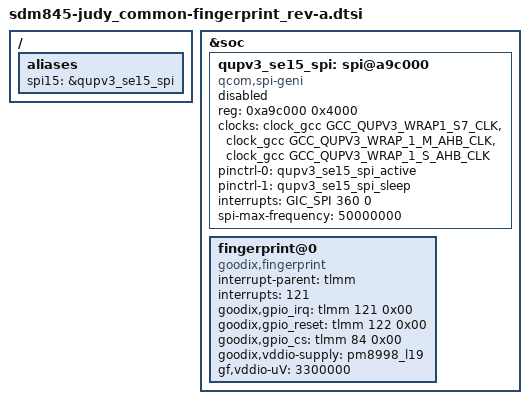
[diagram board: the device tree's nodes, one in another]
/* Copyright (c) 2017, The Linux Foundation. All rights reserved.
 *
 * This program is free software; you can redistribute it and/or modify
 * it under the terms of the GNU General Public License version 2 and
 * only version 2 as published by the Free Software Foundation.
 *
 * This program is distributed in the hope that it will be useful,
 * but WITHOUT ANY WARRANTY; without even the implied warranty of
 * MERCHANTABILITY or FITNESS FOR A PARTICULAR PURPOSE.  See the
 * GNU General Public License for more details.
 */
/{
	aliases {
		spi15 = &qupv3_se15_spi;
	};
/*
	reserved-memory {
		removed_regions: removed_regions@85800000 {
			reg = <0 0x85800000 0 0x2800000>;
		};
	};*/
};

&soc {
/*	qcom_seecom: qseecom@86600000 {
		reg = <0x86600000 0x1A00000>;
	};
*/
	/* PIN CONTROL for gf3208 */

	qupv3_se15_spi: spi@a9c000 { /* QUP15 */
		compatible = "qcom,spi-geni";
		#address-cells = <1>;
		#size-cells = <0>;
		reg = <0xa9c000 0x4000>;
		reg-names = "se_phys";
		clock-names = "se-clk", "m-ahb", "s-ahb";
		clocks = <&clock_gcc GCC_QUPV3_WRAP1_S7_CLK>,
			<&clock_gcc GCC_QUPV3_WRAP_1_M_AHB_CLK>,
			<&clock_gcc GCC_QUPV3_WRAP_1_S_AHB_CLK>;
		pinctrl-names = "default", "sleep";
		pinctrl-0 = <&qupv3_se15_spi_active>;
		pinctrl-1 = <&qupv3_se15_spi_sleep>;
		interrupts = <GIC_SPI 360 0>;
		spi-max-frequency = <50000000>;
		status = "disable";
	};
};

&soc{
	fingerprint@0 {
		status = "ok";
    		compatible = "goodix,fingerprint";

		interrupt-parent = <&tlmm>;
		interrupts = <121>;

		goodix,gpio_irq = <&tlmm 121 0x00>;
		goodix,gpio_reset = <&tlmm 122 0x00>;
		goodix,gpio_cs  = <&tlmm 84 0x00>;
		goodix,vddio-supply = <&pm8998_l19>;
		gf,vddio-uV = <3300000>;
	};
};


